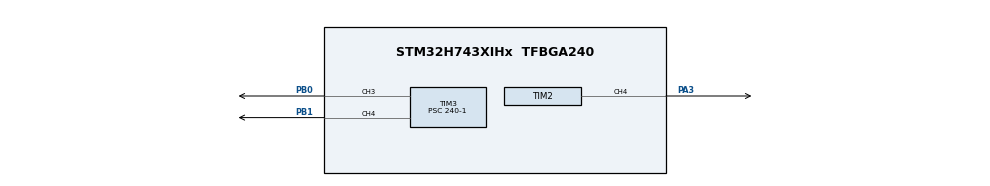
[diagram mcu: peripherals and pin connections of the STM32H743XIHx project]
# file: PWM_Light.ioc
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CORTEX_M7.default_mode_Activation=1
Mcu.Family=STM32H7
Mcu.Name=STM32H743XIHx
Mcu.Package=TFBGA240
NVIC.PriorityGroup=NVIC_PRIORITYGROUP_4
PA3.Signal=S_TIM2_CH4
PB0.Signal=S_TIM3_CH3
PB1.Signal=S_TIM3_CH4
PH0-OSC_IN\ (PH0).Mode=HSE-External-Oscillator
PH0-OSC_IN\ (PH0).Signal=RCC_OSC_IN
PH1-OSC_OUT\ (PH1).Mode=HSE-External-Oscillator
PH1-OSC_OUT\ (PH1).Signal=RCC_OSC_OUT
ProjectManager.HeapSize=0x200
ProjectManager.StackSize=0x400
ProjectManager.TargetToolchain=STM32CubeIDE
RCC.ADCFreq_Value=129000000
RCC.APB1Freq_Value=120000000
RCC.APB2Freq_Value=120000000
RCC.APB3Freq_Value=120000000
RCC.APB4Freq_Value=120000000
RCC.CortexFreq_Value=480000000
RCC.D1PPRE=RCC_APB3_DIV2
RCC.D2PPRE1=RCC_APB1_DIV2
RCC.D2PPRE2=RCC_APB2_DIV2
RCC.D3PPRE=RCC_APB4_DIV2
RCC.DIVM1=4
RCC.DIVN1=60
RCC.HCLKFreq_Value=240000000
RCC.HPRE=RCC_HCLK_DIV2
RCC.PLL2FRACN=0
RCC.PLL3FRACN=0
RCC.PLLFRACN=0
RCC.SYSCLKFreq_VALUE=480000000
RCC.SYSCLKSource=RCC_SYSCLKSOURCE_PLLCLK
RCC.USBFreq_Value=480000000
SH.S_TIM2_CH4.0=TIM2_CH4,PWM Generation4 CH4
SH.S_TIM3_CH3.0=TIM3_CH3,PWM Generation3 CH3
SH.S_TIM3_CH4.0=TIM3_CH4,PWM Generation4 CH4
TIM2.Channel-PWM\ Generation4\ CH4=TIM_CHANNEL_4
TIM2.Period=100-1
TIM2.Prescaler=240-1
TIM2.Pulse-PWM\ Generation4\ CH4=30
TIM3.Channel-PWM\ Generation3\ CH3=TIM_CHANNEL_3
TIM3.Channel-PWM\ Generation4\ CH4=TIM_CHANNEL_4
TIM3.Period=100-1
TIM3.Prescaler=240-1
TIM3.Pulse-PWM\ Generation3\ CH3=50
TIM3.Pulse-PWM\ Generation4\ CH4=70
VP_TIM2_VS_ClockSourceINT.Mode=Internal
VP_TIM3_VS_ClockSourceINT.Mode=Internal
board=custom

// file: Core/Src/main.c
/* USER CODE BEGIN Header */
/**
  ******************************************************************************
  * @file           : main.c
  * @brief          : Main program body
  ******************************************************************************
  * @attention
  *
  * Copyright (c) 2024 STMicroelectronics.
  * All rights reserved.
  *
  * This software is licensed under terms that can be found in the LICENSE file
  * in the root directory of this software component.
  * If no LICENSE file comes with this software, it is provided AS-IS.
  *
  ******************************************************************************
  */
/* USER CODE END Header */
#include "main.h"

TIM_HandleTypeDef htim2;
TIM_HandleTypeDef htim3;

void SystemClock_Config(void);
static void MPU_Config(void);
static void MX_GPIO_Init(void);
static void MX_TIM3_Init(void);
static void MX_TIM2_Init(void);

int main(void)
{

  /* MPU Configuration--------------------------------------------------------*/
  MPU_Config();

  /* MCU Configuration--------------------------------------------------------*/

  /* Reset of all peripherals, Initializes the Flash interface and the Systick. */
  HAL_Init();

  /* Configure the system clock */
  SystemClock_Config();

  /* Initialize all configured peripherals */
  MX_GPIO_Init();
  MX_TIM3_Init();
  MX_TIM2_Init();
  /* USER CODE BEGIN 2 */
  HAL_TIM_PWM_Start(&htim2, TIM_CHANNEL_4);
  /* USER CODE END 2 */

  /* Infinite loop */
  /* USER CODE BEGIN WHILE */
  while (1)
  {
	  for (int i = 0; i < 100; i++)
	  {
		  __HAL_TIM_SET_COMPARE(&htim2, TIM_CHANNEL_4, i);
		  HAL_Delay(10);
	  }
	  for (int i = 100; i > 0; i--)
	  {
		  __HAL_TIM_SET_COMPARE(&htim2, TIM_CHANNEL_4, i);
		  HAL_Delay(10);
	  }
    /* USER CODE END WHILE */

  }
}

void SystemClock_Config(void)
{
  RCC_OscInitTypeDef RCC_OscInitStruct = {0};
  RCC_ClkInitTypeDef RCC_ClkInitStruct = {0};

  /** Supply configuration update enable
  */
  HAL_PWREx_ConfigSupply(PWR_LDO_SUPPLY);

  /** Configure the main internal regulator output voltage
  */
  __HAL_PWR_VOLTAGESCALING_CONFIG(PWR_REGULATOR_VOLTAGE_SCALE1);

  while(!__HAL_PWR_GET_FLAG(PWR_FLAG_VOSRDY)) {}

  __HAL_RCC_SYSCFG_CLK_ENABLE();
  __HAL_PWR_VOLTAGESCALING_CONFIG(PWR_REGULATOR_VOLTAGE_SCALE0);

  while(!__HAL_PWR_GET_FLAG(PWR_FLAG_VOSRDY)) {}

  /** Initializes the RCC Oscillators according to the specified parameters
  * in the RCC_OscInitTypeDef structure.
  */
  RCC_OscInitStruct.OscillatorType = RCC_OSCILLATORTYPE_HSI;
  RCC_OscInitStruct.HSIState = RCC_HSI_DIV1;
  RCC_OscInitStruct.HSICalibrationValue = RCC_HSICALIBRATION_DEFAULT;
  RCC_OscInitStruct.PLL.PLLState = RCC_PLL_ON;
  RCC_OscInitStruct.PLL.PLLSource = RCC_PLLSOURCE_HSI;
  RCC_OscInitStruct.PLL.PLLM = 4;
  RCC_OscInitStruct.PLL.PLLN = 60;
  RCC_OscInitStruct.PLL.PLLP = 2;
  RCC_OscInitStruct.PLL.PLLQ = 2;
  RCC_OscInitStruct.PLL.PLLR = 2;
  RCC_OscInitStruct.PLL.PLLRGE = RCC_PLL1VCIRANGE_3;
  RCC_OscInitStruct.PLL.PLLVCOSEL = RCC_PLL1VCOWIDE;
  RCC_OscInitStruct.PLL.PLLFRACN = 0;
  if (HAL_RCC_OscConfig(&RCC_OscInitStruct) != HAL_OK)
  {
    Error_Handler();
  }

  /** Initializes the CPU, AHB and APB buses clocks
  */
  RCC_ClkInitStruct.ClockType = RCC_CLOCKTYPE_HCLK|RCC_CLOCKTYPE_SYSCLK
                              |RCC_CLOCKTYPE_PCLK1|RCC_CLOCKTYPE_PCLK2
                              |RCC_CLOCKTYPE_D3PCLK1|RCC_CLOCKTYPE_D1PCLK1;
  RCC_ClkInitStruct.SYSCLKSource = RCC_SYSCLKSOURCE_PLLCLK;
  RCC_ClkInitStruct.SYSCLKDivider = RCC_SYSCLK_DIV1;
  RCC_ClkInitStruct.AHBCLKDivider = RCC_HCLK_DIV2;
  RCC_ClkInitStruct.APB3CLKDivider = RCC_APB3_DIV2;
  RCC_ClkInitStruct.APB1CLKDivider = RCC_APB1_DIV2;
  RCC_ClkInitStruct.APB2CLKDivider = RCC_APB2_DIV2;
  RCC_ClkInitStruct.APB4CLKDivider = RCC_APB4_DIV2;

  if (HAL_RCC_ClockConfig(&RCC_ClkInitStruct, FLASH_LATENCY_4) != HAL_OK)
  {
    Error_Handler();
  }
}

static void MX_TIM2_Init(void)
{

  TIM_ClockConfigTypeDef sClockSourceConfig = {0};
  TIM_MasterConfigTypeDef sMasterConfig = {0};
  TIM_OC_InitTypeDef sConfigOC = {0};

  htim2.Instance = TIM2;
  htim2.Init.Prescaler = 240-1;
  htim2.Init.CounterMode = TIM_COUNTERMODE_UP;
  htim2.Init.Period = 100-1;
  htim2.Init.ClockDivision = TIM_CLOCKDIVISION_DIV1;
  htim2.Init.AutoReloadPreload = TIM_AUTORELOAD_PRELOAD_DISABLE;
  if (HAL_TIM_Base_Init(&htim2) != HAL_OK)
  {
    Error_Handler();
  }
  sClockSourceConfig.ClockSource = TIM_CLOCKSOURCE_INTERNAL;
  if (HAL_TIM_ConfigClockSource(&htim2, &sClockSourceConfig) != HAL_OK)
  {
    Error_Handler();
  }
  if (HAL_TIM_PWM_Init(&htim2) != HAL_OK)
  {
    Error_Handler();
  }
  sMasterConfig.MasterOutputTrigger = TIM_TRGO_RESET;
  sMasterConfig.MasterSlaveMode = TIM_MASTERSLAVEMODE_DISABLE;
  if (HAL_TIMEx_MasterConfigSynchronization(&htim2, &sMasterConfig) != HAL_OK)
  {
    Error_Handler();
  }
  sConfigOC.OCMode = TIM_OCMODE_PWM1;
  sConfigOC.Pulse = 30;
  sConfigOC.OCPolarity = TIM_OCPOLARITY_HIGH;
  sConfigOC.OCFastMode = TIM_OCFAST_DISABLE;
  if (HAL_TIM_PWM_ConfigChannel(&htim2, &sConfigOC, TIM_CHANNEL_4) != HAL_OK)
  {
    Error_Handler();
  }
  HAL_TIM_MspPostInit(&htim2);

}

static void MX_TIM3_Init(void)
{

  TIM_ClockConfigTypeDef sClockSourceConfig = {0};
  TIM_MasterConfigTypeDef sMasterConfig = {0};
  TIM_OC_InitTypeDef sConfigOC = {0};

  htim3.Instance = TIM3;
  htim3.Init.Prescaler = 240-1;
  htim3.Init.CounterMode = TIM_COUNTERMODE_UP;
  htim3.Init.Period = 100-1;
  htim3.Init.ClockDivision = TIM_CLOCKDIVISION_DIV1;
  htim3.Init.AutoReloadPreload = TIM_AUTORELOAD_PRELOAD_DISABLE;
  if (HAL_TIM_Base_Init(&htim3) != HAL_OK)
  {
    Error_Handler();
  }
  sClockSourceConfig.ClockSource = TIM_CLOCKSOURCE_INTERNAL;
  if (HAL_TIM_ConfigClockSource(&htim3, &sClockSourceConfig) != HAL_OK)
  {
    Error_Handler();
  }
  if (HAL_TIM_PWM_Init(&htim3) != HAL_OK)
  {
    Error_Handler();
  }
  sMasterConfig.MasterOutputTrigger = TIM_TRGO_RESET;
  sMasterConfig.MasterSlaveMode = TIM_MASTERSLAVEMODE_DISABLE;
  if (HAL_TIMEx_MasterConfigSynchronization(&htim3, &sMasterConfig) != HAL_OK)
  {
    Error_Handler();
  }
  sConfigOC.OCMode = TIM_OCMODE_PWM1;
  sConfigOC.Pulse = 50;
  sConfigOC.OCPolarity = TIM_OCPOLARITY_HIGH;
  sConfigOC.OCFastMode = TIM_OCFAST_DISABLE;
  if (HAL_TIM_PWM_ConfigChannel(&htim3, &sConfigOC, TIM_CHANNEL_3) != HAL_OK)
  {
    Error_Handler();
  }
  sConfigOC.Pulse = 70;
  if (HAL_TIM_PWM_ConfigChannel(&htim3, &sConfigOC, TIM_CHANNEL_4) != HAL_OK)
  {
    Error_Handler();
  }
  HAL_TIM_MspPostInit(&htim3);

}

static void MX_GPIO_Init(void)
{

  /* GPIO Ports Clock Enable */
  __HAL_RCC_GPIOH_CLK_ENABLE();
  __HAL_RCC_GPIOB_CLK_ENABLE();
  __HAL_RCC_GPIOA_CLK_ENABLE();

}

 /* MPU Configuration */

void MPU_Config(void)
{
  MPU_Region_InitTypeDef MPU_InitStruct = {0};

  /* Disables the MPU */
  HAL_MPU_Disable();

  /** Initializes and configures the Region and the memory to be protected
  */
  MPU_InitStruct.Enable = MPU_REGION_ENABLE;
  MPU_InitStruct.Number = MPU_REGION_NUMBER0;
  MPU_InitStruct.BaseAddress = 0x0;
  MPU_InitStruct.Size = MPU_REGION_SIZE_4GB;
  MPU_InitStruct.SubRegionDisable = 0x87;
  MPU_InitStruct.TypeExtField = MPU_TEX_LEVEL0;
  MPU_InitStruct.AccessPermission = MPU_REGION_NO_ACCESS;
  MPU_InitStruct.DisableExec = MPU_INSTRUCTION_ACCESS_DISABLE;
  MPU_InitStruct.IsShareable = MPU_ACCESS_SHAREABLE;
  MPU_InitStruct.IsCacheable = MPU_ACCESS_NOT_CACHEABLE;
  MPU_InitStruct.IsBufferable = MPU_ACCESS_NOT_BUFFERABLE;

  HAL_MPU_ConfigRegion(&MPU_InitStruct);
  /* Enables the MPU */
  HAL_MPU_Enable(MPU_PRIVILEGED_DEFAULT);

}

void Error_Handler(void)
{
  __disable_irq();
  while (1)
  {
  }
}
